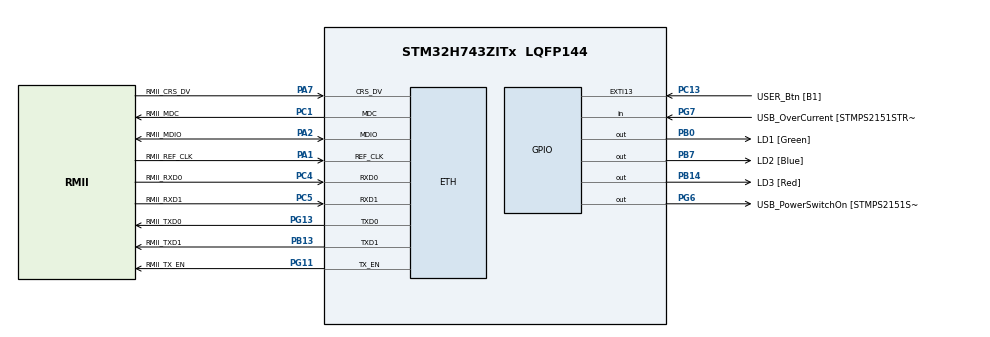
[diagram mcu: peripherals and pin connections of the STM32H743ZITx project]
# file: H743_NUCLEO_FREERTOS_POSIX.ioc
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CORTEX_M7.AccessPermission-Cortex_Memory_Protection_Unit_Region1_Settings=MPU_REGION_FULL_ACCESS
CORTEX_M7.AccessPermission-Cortex_Memory_Protection_Unit_Region2_Settings=MPU_REGION_FULL_ACCESS
CORTEX_M7.BaseAddress-Cortex_Memory_Protection_Unit_Region1_Settings=0x30040000
CORTEX_M7.BaseAddress-Cortex_Memory_Protection_Unit_Region2_Settings=0
CORTEX_M7.CPU_DCache=Enabled
CORTEX_M7.CPU_ICache=Enabled
CORTEX_M7.DisableExec-Cortex_Memory_Protection_Unit_Region0_Settings=MPU_INSTRUCTION_ACCESS_DISABLE
CORTEX_M7.DisableExec-Cortex_Memory_Protection_Unit_Region1_Settings=MPU_INSTRUCTION_ACCESS_DISABLE
CORTEX_M7.DisableExec-Cortex_Memory_Protection_Unit_Region2_Settings=MPU_INSTRUCTION_ACCESS_DISABLE
CORTEX_M7.Enable-Cortex_Memory_Protection_Unit_Region0_Settings=MPU_REGION_ENABLE
CORTEX_M7.Enable-Cortex_Memory_Protection_Unit_Region1_Settings=MPU_REGION_ENABLE
CORTEX_M7.Enable-Cortex_Memory_Protection_Unit_Region2_Settings=MPU_REGION_ENABLE
CORTEX_M7.IsBufferable-Cortex_Memory_Protection_Unit_Region1_Settings=MPU_ACCESS_NOT_BUFFERABLE
CORTEX_M7.IsBufferable-Cortex_Memory_Protection_Unit_Region2_Settings=MPU_ACCESS_BUFFERABLE
CORTEX_M7.IsCacheable-Cortex_Memory_Protection_Unit_Region2_Settings=MPU_ACCESS_NOT_CACHEABLE
CORTEX_M7.IsShareable-Cortex_Memory_Protection_Unit_Region0_Settings=MPU_ACCESS_SHAREABLE
CORTEX_M7.IsShareable-Cortex_Memory_Protection_Unit_Region2_Settings=MPU_ACCESS_SHAREABLE
CORTEX_M7.MPU_Control=MPU_PRIVILEGED_DEFAULT
CORTEX_M7.Size-Cortex_Memory_Protection_Unit_Region0_Settings=MPU_REGION_SIZE_4GB
CORTEX_M7.Size-Cortex_Memory_Protection_Unit_Region1_Settings=MPU_REGION_SIZE_32KB
CORTEX_M7.Size-Cortex_Memory_Protection_Unit_Region2_Settings=MPU_REGION_SIZE_256B
CORTEX_M7.SubRegionDisable-Cortex_Memory_Protection_Unit_Region0_Settings=0x87
CORTEX_M7.TypeExtField-Cortex_Memory_Protection_Unit_Region1_Settings=MPU_TEX_LEVEL1
CORTEX_M7.TypeExtField-Cortex_Memory_Protection_Unit_Region2_Settings=MPU_TEX_LEVEL0
ETH.MediaInterface=HAL_ETH_RMII_MODE
ETH.RxBuffLen=1524
FREERTOS.Tasks01=defaultTask,24,256,StartDefaultTask,Default,NULL,Dynamic,NULL,NULL;posix,8,128,prvMainPosixTask,As external,NULL,Dynamic,NULL,NULL
FREERTOS.Timers01=myTimer01,Callback01,osTimerPeriodic,Default,NULL,Dynamic,NULL
FREERTOS.configENABLE_FPU=0
FREERTOS.configTOTAL_HEAP_SIZE=61440
FREERTOS.configUSE_APPLICATION_TASK_TAG=1
FREERTOS.configUSE_IDLE_HOOK=1
FREERTOS.configUSE_MALLOC_FAILED_HOOK=1
FREERTOS.configUSE_NEWLIB_REENTRANT=1
FREERTOS.configUSE_POSIX_ERRNO=1
FREERTOS.configUSE_TICK_HOOK=1
LWIP.BSP.number=1
LWIP.CHECKSUM_CHECK_ICMP=0
LWIP.CHECKSUM_GEN_ICMP=0
LWIP.IP_ADDRESS=192.168.005.135
LWIP.LWIP_DHCP=0
LWIP.MEM_SIZE=16360
LWIP.NETMASK_ADDRESS=255.255.255.000
LWIP.Version=v2.1.2_Cube
LWIP0.BSP.STBoard=false
LWIP0.BSP.api=BSP_COMPONENT_DRIVER
LWIP0.BSP.component=LAN8742
LWIP0.BSP.instance=LAN8742
LWIP0.BSP.name=Driver_PHY
LWIP0.BSP.semaphore=S_LAN8742
LWIP0.BSP.solution=LAN8742
Mcu.Family=STM32H7
Mcu.Name=STM32H743ZITx
Mcu.Package=LQFP144
NVIC.ETH_IRQn=true\:5\:0\:false\:false\:true\:true\:true\:true\:true
NVIC.PriorityGroup=NVIC_PRIORITYGROUP_4
NVIC.TIM6_DAC_IRQn=true\:15\:0\:false\:false\:true\:false\:false\:true\:true
NVIC.TimeBase=TIM6_DAC_IRQn
NVIC.TimeBaseIP=TIM6
PA1.GPIO_Label=RMII_REF_CLK
PA1.GPIO_Speed=GPIO_SPEED_FREQ_VERY_HIGH
PA1.Mode=RMII
PA1.Signal=ETH_REF_CLK
PA10.GPIO_Label=USB_ID
PA10.Signal=USB_OTG_FS_ID
PA11.GPIO_Label=USB_DM
PA11.Signal=USB_OTG_FS_DM
PA12.GPIO_Label=USB_DP
PA12.Signal=USB_OTG_FS_DP
PA13\ (JTMS/SWDIO).Mode=Serial_Wire
PA13\ (JTMS/SWDIO).Signal=DEBUG_JTMS-SWDIO
PA14\ (JTCK/SWCLK).Mode=Serial_Wire
PA14\ (JTCK/SWCLK).Signal=DEBUG_JTCK-SWCLK
PA2.GPIO_Label=RMII_MDIO
PA2.GPIO_Speed=GPIO_SPEED_FREQ_VERY_HIGH
PA2.Mode=RMII
PA2.Signal=ETH_MDIO
PA7.GPIO_Label=RMII_CRS_DV
PA7.GPIO_Speed=GPIO_SPEED_FREQ_VERY_HIGH
PA7.Mode=RMII
PA7.Signal=ETH_CRS_DV
PA8.GPIO_Label=USB_SOF [TP1]
PA8.Signal=USB_OTG_FS_SOF
PA9.GPIO_Label=USB_VBUS
PA9.Signal=USB_OTG_FS_VBUS
PB0.GPIO_Label=LD1 [Green]
PB0.Signal=GPIO_Output
PB13.GPIO_Label=RMII_TXD1
PB13.GPIO_Speed=GPIO_SPEED_FREQ_VERY_HIGH
PB13.Mode=RMII
PB13.Signal=ETH_TXD1
PB14.GPIO_Label=LD3 [Red]
PB14.Signal=GPIO_Output
PB7.GPIO_Label=LD2 [Blue]
PB7.Signal=GPIO_Output
PC1.GPIO_Label=RMII_MDC
PC1.GPIO_Speed=GPIO_SPEED_FREQ_VERY_HIGH
PC1.Mode=RMII
PC1.Signal=ETH_MDC
PC13.GPIO_Label=USER_Btn [B1]
PC13.Signal=GPXTI13
PC14-OSC32_IN\ (OSC32_IN).Signal=RCC_OSC32_IN
PC15-OSC32_OUT\ (OSC32_OUT).Signal=RCC_OSC32_OUT
PC4.GPIO_Label=RMII_RXD0
PC4.GPIO_Speed=GPIO_SPEED_FREQ_VERY_HIGH
PC4.Mode=RMII
PC4.Signal=ETH_RXD0
PC5.GPIO_Label=RMII_RXD1
PC5.GPIO_Speed=GPIO_SPEED_FREQ_VERY_HIGH
PC5.Mode=RMII
PC5.Signal=ETH_RXD1
PD8.GPIO_Label=STLK_RX [STM32F103CBT6_PA3]
PD8.Signal=USART3_TX
PD9.GPIO_Label=STLK_TX [STM32F103CBT6_PA2]
PD9.Signal=USART3_RX
PG11.GPIO_Label=RMII_TX_EN
PG11.GPIO_Speed=GPIO_SPEED_FREQ_VERY_HIGH
PG11.Mode=RMII
PG11.Signal=ETH_TX_EN
PG13.GPIO_Label=RMII_TXD0
PG13.GPIO_Speed=GPIO_SPEED_FREQ_VERY_HIGH
PG13.Mode=RMII
PG13.Signal=ETH_TXD0
PG6.GPIO_Label=USB_PowerSwitchOn [STMPS2151STR_EN]
PG6.Signal=GPIO_Output
PG7.GPIO_Label=USB_OverCurrent [STMPS2151STR_FAULT]
PG7.Signal=GPIO_Input
PH0-OSC_IN\ (PH0).GPIO_Label=MCO
PH0-OSC_IN\ (PH0).Mode=HSE-External-Clock-Source
PH0-OSC_IN\ (PH0).Signal=RCC_OSC_IN
ProjectManager.HeapSize=0x400
ProjectManager.StackSize=0x1000
ProjectManager.TargetToolchain=STM32CubeIDE
RCC.48MHZClocksFreq_Value=24000000
RCC.ADCFreq_Value=16125000
RCC.AHBFreq_Value=216000000
RCC.APB1CLKDivider=RCC_HCLK_DIV4
RCC.APB1Freq_Value=100000000
RCC.APB1TimFreq_Value=108000000
RCC.APB2CLKDivider=RCC_HCLK_DIV2
RCC.APB2Freq_Value=100000000
RCC.APB2TimFreq_Value=216000000
RCC.APB3Freq_Value=100000000
RCC.APB4Freq_Value=100000000
RCC.CortexFreq_Value=400000000
RCC.D1PPRE=RCC_APB3_DIV2
RCC.D2PPRE1=RCC_APB1_DIV2
RCC.D2PPRE2=RCC_APB2_DIV2
RCC.D3PPRE=RCC_APB4_DIV2
RCC.DIVM1=1
RCC.DIVN1=100
RCC.DIVQ1=4
RCC.HCLKFreq_Value=200000000
RCC.HPRE=RCC_HCLK_DIV2
RCC.HSE_VALUE=8000000
RCC.HSI_VALUE=64000000
RCC.LockedElements=D1CPREOutput,AHBOutput
RCC.PLLFRACN=0
RCC.PLLM=25
RCC.PLLMUL=RCC_PLL_MUL9
RCC.PLLN=432
RCC.PLLQ=9
RCC.PLLSourceVirtual=RCC_PLLSOURCE_HSE
RCC.PRESCALERUSB=RCC_USBCLKSOURCE_PLL_DIV1_5
RCC.PWR_Regulator_Voltage_Scale=PWR_REGULATOR_VOLTAGE_SCALE1
RCC.SYSCLKFreq_VALUE=400000000
RCC.SYSCLKSource=RCC_SYSCLKSOURCE_PLLCLK
RCC.SYSCLKSourceVirtual=RCC_SYSCLKSOURCE_PLLCLK
RCC.USBFreq_Value=200000000
RCC.VCOOutputFreq_Value=432000000
VP_CRC_VS_CRC.Mode=CRC_Activate
VP_FREERTOS_VS_CMSIS_V2.Mode=CMSIS_V2
VP_LWIP_VS_Enabled.Mode=Enabled
VP_SYS_VS_tim6.Mode=TIM6
board=NUCLEO-H743ZI

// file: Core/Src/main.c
/* USER CODE BEGIN Header */
/**
 ******************************************************************************
 * @file           : main.c
 * @brief          : Main program body
 ******************************************************************************
 * @attention
 *
 * Copyright (c) 2022 STMicroelectronics.
 * All rights reserved.
 *
 * This software is licensed under terms that can be found in the LICENSE file
 * in the root directory of this software component.
 * If no LICENSE file comes with this software, it is provided AS-IS.
 *
 ******************************************************************************
 */
/* USER CODE END Header */
#include "main.h"
#include "cmsis_os.h"
#include "crc.h"
#include "lwip.h"
#include "gpio.h"

void SystemClock_Config(void);
static void MPU_Config(void);
void MX_FREERTOS_Init(void);

int main(void)
{

  /* MPU Configuration--------------------------------------------------------*/
  MPU_Config();

  /* Enable I-Cache---------------------------------------------------------*/
  SCB_EnableICache();

  /* Enable D-Cache---------------------------------------------------------*/
  SCB_EnableDCache();

  /* MCU Configuration--------------------------------------------------------*/

  /* Reset of all peripherals, Initializes the Flash interface and the Systick. */
  HAL_Init();

  /* Configure the system clock */
  SystemClock_Config();

  /* USER CODE BEGIN SysInit */
  /* Enable D2 domain SRAM3 Clock (0x30040000 AXI)*/
  __HAL_RCC_D2SRAM3_CLK_ENABLE();
  /* USER CODE END SysInit */

  /* Initialize all configured peripherals */
  MX_GPIO_Init();
  MX_CRC_Init();

  /* Init scheduler */
  osKernelInitialize();  /* Call init function for freertos objects (in freertos.c) */
  MX_FREERTOS_Init();

  /* Start scheduler */
  osKernelStart();

  /* We should never get here as control is now taken by the scheduler */
  /* Infinite loop */
  while (1) {

  }
}

void SystemClock_Config(void)
{
  RCC_OscInitTypeDef RCC_OscInitStruct = {0};
  RCC_ClkInitTypeDef RCC_ClkInitStruct = {0};

  /** Supply configuration update enable
  */
  HAL_PWREx_ConfigSupply(PWR_LDO_SUPPLY);

  /** Configure the main internal regulator output voltage
  */
  __HAL_PWR_VOLTAGESCALING_CONFIG(PWR_REGULATOR_VOLTAGE_SCALE1);

  while(!__HAL_PWR_GET_FLAG(PWR_FLAG_VOSRDY)) {}

  /** Initializes the RCC Oscillators according to the specified parameters
  * in the RCC_OscInitTypeDef structure.
  */
  RCC_OscInitStruct.OscillatorType = RCC_OSCILLATORTYPE_HSE;
  RCC_OscInitStruct.HSEState = RCC_HSE_BYPASS;
  RCC_OscInitStruct.PLL.PLLState = RCC_PLL_ON;
  RCC_OscInitStruct.PLL.PLLSource = RCC_PLLSOURCE_HSE;
  RCC_OscInitStruct.PLL.PLLM = 1;
  RCC_OscInitStruct.PLL.PLLN = 100;
  RCC_OscInitStruct.PLL.PLLP = 2;
  RCC_OscInitStruct.PLL.PLLQ = 4;
  RCC_OscInitStruct.PLL.PLLR = 2;
  RCC_OscInitStruct.PLL.PLLRGE = RCC_PLL1VCIRANGE_3;
  RCC_OscInitStruct.PLL.PLLVCOSEL = RCC_PLL1VCOWIDE;
  RCC_OscInitStruct.PLL.PLLFRACN = 0;
  if (HAL_RCC_OscConfig(&RCC_OscInitStruct) != HAL_OK)
  {
    Error_Handler();
  }

  /** Initializes the CPU, AHB and APB buses clocks
  */
  RCC_ClkInitStruct.ClockType = RCC_CLOCKTYPE_HCLK|RCC_CLOCKTYPE_SYSCLK
                              |RCC_CLOCKTYPE_PCLK1|RCC_CLOCKTYPE_PCLK2
                              |RCC_CLOCKTYPE_D3PCLK1|RCC_CLOCKTYPE_D1PCLK1;
  RCC_ClkInitStruct.SYSCLKSource = RCC_SYSCLKSOURCE_PLLCLK;
  RCC_ClkInitStruct.SYSCLKDivider = RCC_SYSCLK_DIV1;
  RCC_ClkInitStruct.AHBCLKDivider = RCC_HCLK_DIV2;
  RCC_ClkInitStruct.APB3CLKDivider = RCC_APB3_DIV2;
  RCC_ClkInitStruct.APB1CLKDivider = RCC_APB1_DIV2;
  RCC_ClkInitStruct.APB2CLKDivider = RCC_APB2_DIV2;
  RCC_ClkInitStruct.APB4CLKDivider = RCC_APB4_DIV2;

  if (HAL_RCC_ClockConfig(&RCC_ClkInitStruct, FLASH_LATENCY_2) != HAL_OK)
  {
    Error_Handler();
  }
}

/* MPU Configuration */

void MPU_Config(void)
{
  MPU_Region_InitTypeDef MPU_InitStruct = {0};

  /* Disables the MPU */
  HAL_MPU_Disable();

  /** Initializes and configures the Region and the memory to be protected
  */
  MPU_InitStruct.Enable = MPU_REGION_ENABLE;
  MPU_InitStruct.Number = MPU_REGION_NUMBER0;
  MPU_InitStruct.BaseAddress = 0x0;
  MPU_InitStruct.Size = MPU_REGION_SIZE_4GB;
  MPU_InitStruct.SubRegionDisable = 0x87;
  MPU_InitStruct.TypeExtField = MPU_TEX_LEVEL0;
  MPU_InitStruct.AccessPermission = MPU_REGION_NO_ACCESS;
  MPU_InitStruct.DisableExec = MPU_INSTRUCTION_ACCESS_DISABLE;
  MPU_InitStruct.IsShareable = MPU_ACCESS_SHAREABLE;
  MPU_InitStruct.IsCacheable = MPU_ACCESS_NOT_CACHEABLE;
  MPU_InitStruct.IsBufferable = MPU_ACCESS_NOT_BUFFERABLE;

  HAL_MPU_ConfigRegion(&MPU_InitStruct);

  /** Initializes and configures the Region and the memory to be protected
  */
  MPU_InitStruct.Number = MPU_REGION_NUMBER1;
  MPU_InitStruct.BaseAddress = 0x30040000;
  MPU_InitStruct.Size = MPU_REGION_SIZE_32KB;
  MPU_InitStruct.SubRegionDisable = 0x0;
  MPU_InitStruct.TypeExtField = MPU_TEX_LEVEL1;
  MPU_InitStruct.AccessPermission = MPU_REGION_FULL_ACCESS;
  MPU_InitStruct.IsShareable = MPU_ACCESS_NOT_SHAREABLE;

  HAL_MPU_ConfigRegion(&MPU_InitStruct);

  /** Initializes and configures the Region and the memory to be protected
  */
  MPU_InitStruct.Number = MPU_REGION_NUMBER2;
  MPU_InitStruct.BaseAddress = 0;
  MPU_InitStruct.Size = MPU_REGION_SIZE_256B;
  MPU_InitStruct.TypeExtField = MPU_TEX_LEVEL0;
  MPU_InitStruct.IsShareable = MPU_ACCESS_SHAREABLE;
  MPU_InitStruct.IsBufferable = MPU_ACCESS_BUFFERABLE;

  HAL_MPU_ConfigRegion(&MPU_InitStruct);
  /* Enables the MPU */
  HAL_MPU_Enable(MPU_PRIVILEGED_DEFAULT);

}

void HAL_TIM_PeriodElapsedCallback(TIM_HandleTypeDef *htim)
{
  if (htim->Instance == TIM6) {
    HAL_IncTick();
  }
}

void Error_Handler(void)
{
  __disable_irq();
  while (1) {
  }
}

#ifdef  USE_FULL_ASSERT
/**
  * @brief  Reports the name of the source file and the source line number
  *         where the assert_param error has occurred.
  * @param  file: pointer to the source file name
  * @param  line: assert_param error line source number
  * @retval None
  */
void assert_failed(uint8_t *file, uint32_t line)
{
  /* USER CODE BEGIN 6 */
  /* User can add his own implementation to report the file name and line
     number, ex: printf("Wrong parameters value: file %s on line %d\r\n", file,
     line) */
  /* USER CODE END 6 */
}
#endif /* USE_FULL_ASSERT */

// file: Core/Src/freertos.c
/* USER CODE BEGIN Header */
/**
 ******************************************************************************
 * File Name          : freertos.c
 * Description        : Code for freertos applications
 ******************************************************************************
 * @attention
 *
 * Copyright (c) 2022 STMicroelectronics.
 * All rights reserved.
 *
 * This software is licensed under terms that can be found in the LICENSE file
 * in the root directory of this software component.
 * If no LICENSE file comes with this software, it is provided AS-IS.
 *
 ******************************************************************************
 */
/* USER CODE END Header */

#include "FreeRTOS.h"
#include "task.h"
#include "main.h"
#include "cmsis_os.h"

/* Definitions for defaultTask */
osThreadId_t defaultTaskHandle;
const osThreadAttr_t defaultTask_attributes = {
  .name = "defaultTask",
  .stack_size = 256 * 4,
  .priority = (osPriority_t) osPriorityNormal,
};
/* Definitions for posix */
osThreadId_t posixHandle;
const osThreadAttr_t posix_attributes = {
  .name = "posix",
  .stack_size = 128 * 4,
  .priority = (osPriority_t) osPriorityLow,
};
/* Definitions for myTimer01 */
osTimerId_t myTimer01Handle;
const osTimerAttr_t myTimer01_attributes = {
  .name = "myTimer01"
};

/* USER CODE BEGIN FunctionPrototypes */
extern void prvMainPosixTask(void *opaque);
/* USER CODE END FunctionPrototypes */

void StartDefaultTask(void *argument);
extern void prvMainPosixTask(void *argument);
void Callback01(void *argument);

extern void MX_LWIP_Init(void);
void MX_FREERTOS_Init(void); /* (MISRA C 2004 rule 8.1) */

/* Hook prototypes */
void vApplicationIdleHook(void);
void vApplicationTickHook(void);
void vApplicationMallocFailedHook(void);

/* USER CODE BEGIN 2 */
void vApplicationIdleHook(void) {
  /* vApplicationIdleHook() will only be called if configUSE_IDLE_HOOK is set
  to 1 in FreeRTOSConfig.h. It will be called on each iteration of the idle
  task. It is essential that code added to this hook function never attempts
  to block in any way (for example, call xQueueReceive() with a block time
  specified, or call vTaskDelay()). If the application makes use of the
  vTaskDelete() API function (as this demo application does) then it is also
  important that vApplicationIdleHook() is permitted to return to its calling
  function, because it is the responsibility of the idle task to clean up
  memory allocated by the kernel to any task that has since been deleted. */
}
/* USER CODE END 2 */

/* USER CODE BEGIN 3 */
void vApplicationTickHook(void) {
  /* This function will be called by each tick interrupt if
  configUSE_TICK_HOOK is set to 1 in FreeRTOSConfig.h. User code can be
  added here, but the tick hook is called from an interrupt context, so
  code must not attempt to block, and only the interrupt safe FreeRTOS API
  functions can be used (those that end in FromISR()). */
}
/* USER CODE END 3 */

/* USER CODE BEGIN 5 */
void vApplicationMallocFailedHook(void)
{
   /* vApplicationMallocFailedHook() will only be called if
   configUSE_MALLOC_FAILED_HOOK is set to 1 in FreeRTOSConfig.h. It is a hook
   function that will get called if a call to pvPortMalloc() fails.
   pvPortMalloc() is called internally by the kernel whenever a task, queue,
   timer or semaphore is created. It is also called by various parts of the
   demo application. If heap_1.c or heap_2.c are used, then the size of the
   heap available to pvPortMalloc() is defined by configTOTAL_HEAP_SIZE in
   FreeRTOSConfig.h, and the xPortGetFreeHeapSize() API function can be used
   to query the size of free heap space that remains (although it does not
   provide information on how the remaining heap might be fragmented). */
}
/* USER CODE END 5 */

void MX_FREERTOS_Init(void) {

  /* Create the timer(s) */
  /* creation of myTimer01 */
  myTimer01Handle = osTimerNew(Callback01, osTimerPeriodic, NULL, &myTimer01_attributes);

  /* Create the thread(s) */
  /* creation of defaultTask */
  defaultTaskHandle = osThreadNew(StartDefaultTask, NULL, &defaultTask_attributes);

  /* creation of posix */
  posixHandle = osThreadNew(prvMainPosixTask, NULL, &posix_attributes);

  /* USER CODE BEGIN RTOS_THREADS */
  /* add threads, ... */
  /* Start the task to run POSIX hello world */
  /* USER CODE END RTOS_THREADS */

}

void StartDefaultTask(void *argument)
{
  /* init code for LWIP */
  MX_LWIP_Init();
  for (;;) {
    osDelay(1);
  }
}

/* Callback01 function */
void Callback01(void *argument)
{
}
